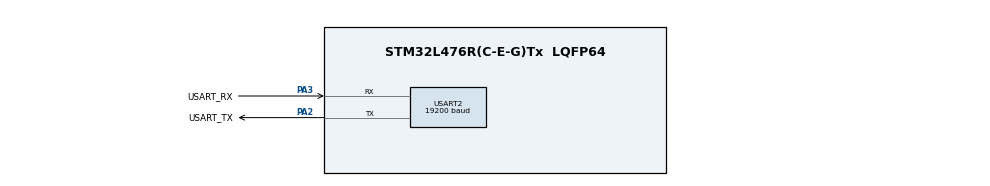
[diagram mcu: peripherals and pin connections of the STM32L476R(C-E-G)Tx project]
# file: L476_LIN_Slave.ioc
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Mcu.Family=STM32L4
Mcu.Name=STM32L476R(C-E-G)Tx
Mcu.Package=LQFP64
NVIC.PriorityGroup=NVIC_PRIORITYGROUP_4
PA2.GPIO_Label=USART_TX
PA2.GPIO_Mode=GPIO_MODE_AF_PP
PA2.GPIO_PuPd=GPIO_NOPULL
PA2.GPIO_Speed=GPIO_SPEED_FREQ_VERY_HIGH
PA2.Mode=LIN
PA2.Signal=USART2_TX
PA3.GPIO_Label=USART_RX
PA3.GPIO_Mode=GPIO_MODE_AF_PP
PA3.GPIO_PuPd=GPIO_NOPULL
PA3.GPIO_Speed=GPIO_SPEED_FREQ_VERY_HIGH
PA3.Mode=LIN
PA3.Signal=USART2_RX
PC14-OSC32_IN\ (PC14).Mode=LSE-External-Oscillator
PC14-OSC32_IN\ (PC14).Signal=RCC_OSC32_IN
PC15-OSC32_OUT\ (PC15).Mode=LSE-External-Oscillator
PC15-OSC32_OUT\ (PC15).Signal=RCC_OSC32_OUT
PH0-OSC_IN\ (PH0).Signal=RCC_OSC_IN
PH1-OSC_OUT\ (PH1).Signal=RCC_OSC_OUT
ProjectManager.HeapSize=0x200
ProjectManager.StackSize=0x400
ProjectManager.TargetToolchain=MDK-ARM V5.32
RCC.ADCFreq_Value=64000000
RCC.AHBFreq_Value=80000000
RCC.APB1Freq_Value=80000000
RCC.APB1TimFreq_Value=80000000
RCC.APB2Freq_Value=80000000
RCC.APB2TimFreq_Value=80000000
RCC.CortexFreq_Value=80000000
RCC.HCLKFreq_Value=80000000
RCC.HSE_VALUE=8000000
RCC.HSI_VALUE=16000000
RCC.MSI_VALUE=4000000
RCC.PLLN=10
RCC.PLLSourceVirtual=RCC_PLLSOURCE_HSI
RCC.PREFETCH_ENABLE=1
RCC.SYSCLKFreq_VALUE=80000000
RCC.SYSCLKSource=RCC_SYSCLKSOURCE_PLLCLK
RCC.USBFreq_Value=64000000
RCC.VCOOutputFreq_Value=160000000
USART2.BaudRate=19200
USART2.DMADisableonRxErrorParam=ADVFEATURE_DMA_DISABLEONRXERROR
USART2.VirtualMode-LIN=VM_LIN
board=NUCLEO-L476RG

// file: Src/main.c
/* USER CODE BEGIN Header */
/**
  ******************************************************************************
  * @file           : main.c
  * @brief          : Main program body
  ******************************************************************************
  * @attention
  *
  * Copyright (c) 2024 STMicroelectronics.
  * All rights reserved.
  *
  * This software is licensed under terms that can be found in the LICENSE file
  * in the root directory of this software component.
  * If no LICENSE file comes with this software, it is provided AS-IS.
  *
  ******************************************************************************
  */
/* USER CODE END Header */
#include "main.h"

void SystemClock_Config(void);
static void MX_GPIO_Init(void);
static void MX_USART2_UART_Init(void);
/* USER CODE BEGIN PFP */
uint8_t LIN_CalculateParity(uint8_t id);
void LIN_ReceiveData(uint8_t *buffer, uint8_t length);
uint8_t LIN_CalculateChecksum(uint8_t *data, uint8_t length);
void LIN_SlaveReceive(uint8_t id, uint8_t *buffer, uint8_t length);
/* USER CODE END PFP */

int main(void)
{

  /* MCU Configuration--------------------------------------------------------*/

  /* Reset of all peripherals, Initializes the Flash interface and the Systick. */
  LL_APB2_GRP1_EnableClock(LL_APB2_GRP1_PERIPH_SYSCFG);
  LL_APB1_GRP1_EnableClock(LL_APB1_GRP1_PERIPH_PWR);

  /* System interrupt init*/
  NVIC_SetPriorityGrouping(NVIC_PRIORITYGROUP_4);

  /* Configure the system clock */
  SystemClock_Config();

  /* Initialize all configured peripherals */
  MX_GPIO_Init();
  MX_USART2_UART_Init();
  /* USER CODE BEGIN 2 */
	uint8_t data_received[4];
  /* USER CODE END 2 */

  /* Infinite loop */
  while (1)
  {
		LIN_SlaveReceive(0x10, data_received, 4);
  }
}

void SystemClock_Config(void)
{
  LL_FLASH_SetLatency(LL_FLASH_LATENCY_4);
  while(LL_FLASH_GetLatency()!= LL_FLASH_LATENCY_4)
  {
  }
  LL_PWR_SetRegulVoltageScaling(LL_PWR_REGU_VOLTAGE_SCALE1);
  while (LL_PWR_IsActiveFlag_VOS() != 0)
  {
  }
  LL_RCC_HSI_Enable();

   /* Wait till HSI is ready */
  while(LL_RCC_HSI_IsReady() != 1)
  {

  }
  LL_RCC_HSI_SetCalibTrimming(16);
  LL_RCC_PLL_ConfigDomain_SYS(LL_RCC_PLLSOURCE_HSI, LL_RCC_PLLM_DIV_1, 10, LL_RCC_PLLR_DIV_2);
  LL_RCC_PLL_EnableDomain_SYS();
  LL_RCC_PLL_Enable();

   /* Wait till PLL is ready */
  while(LL_RCC_PLL_IsReady() != 1)
  {

  }
  LL_RCC_SetSysClkSource(LL_RCC_SYS_CLKSOURCE_PLL);

   /* Wait till System clock is ready */
  while(LL_RCC_GetSysClkSource() != LL_RCC_SYS_CLKSOURCE_STATUS_PLL)
  {

  }
  LL_RCC_SetAHBPrescaler(LL_RCC_SYSCLK_DIV_1);
  LL_RCC_SetAPB1Prescaler(LL_RCC_APB1_DIV_1);
  LL_RCC_SetAPB2Prescaler(LL_RCC_APB2_DIV_1);

  LL_Init1msTick(80000000);

  LL_SetSystemCoreClock(80000000);
}

static void MX_USART2_UART_Init(void)
{

  LL_USART_InitTypeDef USART_InitStruct = {0};

  LL_GPIO_InitTypeDef GPIO_InitStruct = {0};

  LL_RCC_SetUSARTClockSource(LL_RCC_USART2_CLKSOURCE_PCLK1);

  /* Peripheral clock enable */
  LL_APB1_GRP1_EnableClock(LL_APB1_GRP1_PERIPH_USART2);

  LL_AHB2_GRP1_EnableClock(LL_AHB2_GRP1_PERIPH_GPIOA);
  /**USART2 GPIO Configuration
  PA2   ------> USART2_TX
  PA3   ------> USART2_RX
  */
  GPIO_InitStruct.Pin = USART_TX_Pin|USART_RX_Pin;
  GPIO_InitStruct.Mode = LL_GPIO_MODE_ALTERNATE;
  GPIO_InitStruct.Speed = LL_GPIO_SPEED_FREQ_VERY_HIGH;
  GPIO_InitStruct.OutputType = LL_GPIO_OUTPUT_PUSHPULL;
  GPIO_InitStruct.Pull = LL_GPIO_PULL_NO;
  GPIO_InitStruct.Alternate = LL_GPIO_AF_7;
  LL_GPIO_Init(GPIOA, &GPIO_InitStruct);

  USART_InitStruct.BaudRate = 19200;
  USART_InitStruct.DataWidth = LL_USART_DATAWIDTH_8B;
  USART_InitStruct.StopBits = LL_USART_STOPBITS_1;
  USART_InitStruct.Parity = LL_USART_PARITY_NONE;
  USART_InitStruct.TransferDirection = LL_USART_DIRECTION_TX_RX;
  USART_InitStruct.OverSampling = LL_USART_OVERSAMPLING_16;
  LL_USART_Init(USART2, &USART_InitStruct);
  LL_USART_SetLINBrkDetectionLen(USART2, LL_USART_LINBREAK_DETECT_10B);
  LL_USART_DisableDMADeactOnRxErr(USART2);
  LL_USART_ConfigLINMode(USART2);
  LL_USART_Enable(USART2);
  /* USER CODE BEGIN USART2_Init 2 */
	LL_USART_EnableLIN(USART2);
  /* USER CODE END USART2_Init 2 */

}

static void MX_GPIO_Init(void)
{

  /* GPIO Ports Clock Enable */
  LL_AHB2_GRP1_EnableClock(LL_AHB2_GRP1_PERIPH_GPIOC);
  LL_AHB2_GRP1_EnableClock(LL_AHB2_GRP1_PERIPH_GPIOH);
  LL_AHB2_GRP1_EnableClock(LL_AHB2_GRP1_PERIPH_GPIOA);

}

/* USER CODE BEGIN 4 */
uint8_t LIN_CalculateParity(uint8_t id)
{
	uint8_t p0 = ((id >> 0) & 0x01) ^ ((id >> 1) & 0x01) ^ ((id >> 2) & 0x01);
  uint8_t p1 = ~(((id >> 1) & 0x01) ^ ((id >> 3) & 0x01) ^ ((id >> 4) & 0x01) ^ ((id >> 5) & 0x01));
  return (p0 | (p1 << 1)) << 6;
}

void LIN_ReceiveData(uint8_t *buffer, uint8_t length)
{
  for (uint8_t i = 0; i < length; i++)
  {
		// wait until data is available
    while (!LL_USART_IsActiveFlag_RXNE(USART2));
		// read data
    buffer[i] = LL_USART_ReceiveData8(USART2);
  }
}

uint8_t LIN_CalculateChecksum(uint8_t *data, uint8_t length)
{
  uint16_t checksum = 0;
  for (uint8_t i = 0; i < length; i++)
  {
    checksum += data[i];
    if (checksum > 0xFF)
    {
      checksum -= 0xFF;
    }
  }
  return ~checksum;
}

void LIN_SendChecksum(uint8_t *data, uint8_t length)
{
  uint8_t checksum = LIN_CalculateChecksum(data, length);
	// wait until TX ready
	while (!LL_USART_IsActiveFlag_TXE(USART2)){}
  LL_USART_TransmitData8(USART2, checksum);
  // wait until sending process is done
  while (!LL_USART_IsActiveFlag_TC(USART2));
}

void LIN_SlaveReceive(uint8_t id, uint8_t *buffer, uint8_t length)
{
  uint8_t received_id;

  // wait until data is available
  while (!LL_USART_IsActiveFlag_RXNE(USART2));
  received_id = LL_USART_ReceiveData8(USART2);

  // Check received ID, if ID matches, continue to receive
  if (received_id == (id | LIN_CalculateParity(id)))
  {
    // receive data from master
    LIN_ReceiveData(buffer, length);

    // verify checksum
    uint8_t received_checksum = LL_USART_ReceiveData8(USART2);
    if (received_checksum == LIN_CalculateChecksum(buffer, length))
    {
      // data valid
    }
    else
    {
      // handle checksum error
    }
  }
}

/* USER CODE END 4 */

void Error_Handler(void)
{
  __disable_irq();
  while (1)
  {
  }
}
